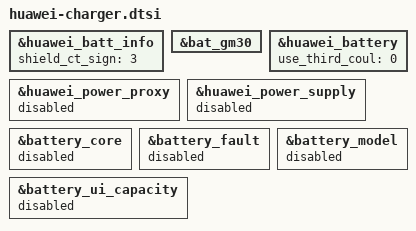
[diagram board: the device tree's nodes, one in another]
#include "../huawei_charger/mt6853_ang_huawei_charger.dtsi"

&huawei_batt_info {
	shield_ct_sign = <3>;
};

&bat_gm30 {
	status = "ok";
};

&huawei_battery {
	use_third_coul = <0>;
};

&huawei_power_proxy  {
	status = "disabled";
};
&huawei_power_supply {
	status = "disabled";
};
&battery_core {
	status = "disabled";
};
&battery_fault {
	status = "disabled";
};
&battery_model {
	status = "disabled";
};
&battery_ui_capacity {
	status = "disabled";
};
